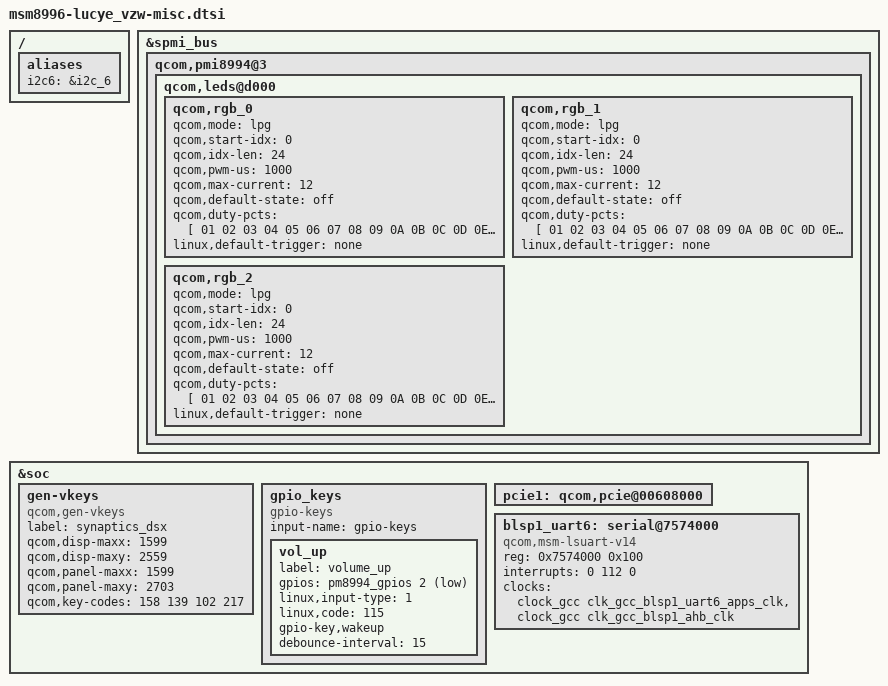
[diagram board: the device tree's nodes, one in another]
/* Copyright (c) 2015, The Linux Foundation. All rights reserved.
 *
 * This program is free software; you can redistribute it and/or modify
 * it under the terms of the GNU General Public License version 2 and
 * only version 2 as published by the Free Software Foundation.
 *
 * This program is distributed in the hope that it will be useful,
 * but WITHOUT ANY WARRANTY; without even the implied warranty of
 * MERCHANTABILITY or FITNESS FOR A PARTICULAR PURPOSE.  See the
 * GNU General Public License for more details.
 */

/{
	aliases {
		i2c6 = &i2c_6;
	};
};

/* LED setting */
&spmi_bus {
	qcom,pmi8994@3 {
		qcom,leds@d000 {
			status = "okay";
			qcom,rgb_0 {
				qcom,mode = "lpg";
				qcom,start-idx = <0>;
				qcom,idx-len = <24>;
				qcom,pwm-us = <1000>;
				qcom,max-current = <12>;
				qcom,default-state = "off";
				qcom,duty-pcts = [
					 01 02 03 04 05 06 07 08
					 09 0A 0B 0C 0D 0E 0F 10
					 11 12 13 14 15 16 17 18
					 ];
				linux,default-trigger = "none";
			};

			qcom,rgb_1 {
				qcom,mode = "lpg";
				qcom,start-idx = <0>;
				qcom,idx-len = <24>;
				qcom,pwm-us = <1000>;
				qcom,max-current = <12>;
				qcom,default-state = "off";
				qcom,duty-pcts = [
					 01 02 03 04 05 06 07 08
					 09 0A 0B 0C 0D 0E 0F 10
					 11 12 13 14 15 16 17 18
					 ];
				linux,default-trigger = "none";
			};

			qcom,rgb_2 {
				qcom,mode = "lpg";
				qcom,start-idx = <0>;
				qcom,idx-len = <24>;
				qcom,pwm-us = <1000>;
				qcom,max-current = <12>;
				qcom,default-state = "off";
				qcom,duty-pcts = [
					 01 02 03 04 05 06 07 08
					 09 0A 0B 0C 0D 0E 0F 10
					 11 12 13 14 15 16 17 18
					 ];
				linux,default-trigger = "none";
			};
		};
	};
};
&soc {
	gen-vkeys {
		compatible = "qcom,gen-vkeys";
		label = "synaptics_dsx";
		qcom,disp-maxx = <1599>;
		qcom,disp-maxy = <2559>;
		qcom,panel-maxx = <1599>;
		qcom,panel-maxy = <2703>;
		qcom,key-codes = <158 139 102 217>;
	};

	gpio_keys {
		compatible = "gpio-keys";
		input-name = "gpio-keys";

		vol_up {
			label = "volume_up";
			gpios = <&pm8994_gpios 2 0x1>;
			linux,input-type = <1>;
			linux,code = <115>;
			gpio-key,wakeup;
			debounce-interval = <15>;
		};
	};

	pcie1: qcom,pcie@00608000 {
		/delete-property/ perst-gpio;
		/delete-property/ wake-gpio;
	};

	blsp1_uart6: serial@7574000 {
		compatible = "qcom,msm-lsuart-v14";
		reg = <0x7574000 0x100>;
		interrupts = <0 112 0>;
		status = "ok";
		clock-names = "core_clk", "iface_clk";
		clocks = <&clock_gcc clk_gcc_blsp1_uart6_apps_clk>,
				<&clock_gcc clk_gcc_blsp1_ahb_clk>;
	};
};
